# VIMS register map
Vendor: Texas Instruments
Peripheral module from a debugger description file (folder UCD3138R032RJA).
Registers are 32-bit, read-write, no defined reset value unless marked. A register's access mark holds for its fields unless they carry their own. Offsets are as the file gives them; lines under a group give offsets from that group; [hi:lo] are bit positions; {n}, {i} and the like mark numbered series; 'fields as' and 'values as' point back to an identical list; <NAME> marks a mode.

## VIMS — Versatile Instruction Memory System Controls memory access to the Flash and encapsulates the following instruction memories: - Boot ROM - Caches INTERNAL_NOTE: [Functional Spec](https://confluence.itg.ti.com/display/LPRF/Functional+Specification) [Simple Block Diagram](https://confluence.itg.ti.com/display/LPRF/Functional+Specification)
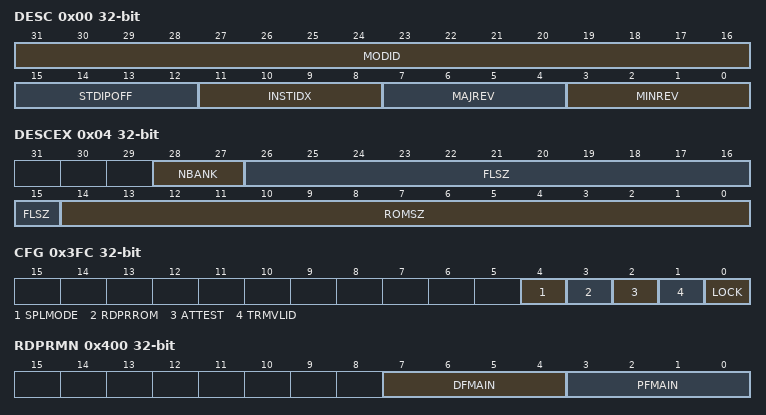
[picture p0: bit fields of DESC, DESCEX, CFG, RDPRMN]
0x00 DESC ro — Description Register. This register provides IP module ID, revision information, instance index and standard MMR registers offset.
  [31:16] MODID — Module identification contains a unique peripheral identification number.
  [15:12] STDIPOFF — Standard IP MMR block offset. Standard IP MMRs are the set of from aggregated IRQ registers till DTB. 0: Standard IP MMRs do not exist 0x1-0xF: Standard IP MMRs begin at offset of (64*[STDIPOFF] from the base IP address)
  [11:8] INSTIDX — IP Instance ID number. If multiple instances of IP exist in the device, this field can identify the instance number (0-15).
  [7:4] MAJREV — Major revision of IP
  [3:0] MINREV — Minor revision of IP
0x04 DESCEX ro — Extended Description Register.This register describes the configuration of VIMS.
  [28:27] NBANK — Number of Flash banks
  [26:15] FLSZ — FLASH size in Kilo Bytes. The total FLASH size is (FLSZ + 1) KB
  [14:0] ROMSZ — ROM size in Kilo Bytes. The total ROM size is (ROMSZ + 1) KB
0x08 FLWS1T — Flash Wait State 1T. This register is used to specify the number of waitstates necessary for accessing the flash in 1T mode.
  [3:0] VAL — Flash read wait states for 1T accesses
    {v}=WS{v} (Wait state value {v}) (v=0..15)
0x0C FLWS2T — Flash Wait State 1T. This register is used to specify the number of waitstates necessary for accessing the flash in 2T mode. This register is writable only when [CFG.LOCK] is 1
  [3:0] VAL — Flash read wait states for 2T accesses
    {v}=WS{v} (Wait state value {v}) (v=0..15)
0x18 PTRMC0 — FLASH Pump trim Bank 0. This register stores different PUMP trims. This register is writable only when [CFG.LOCK] is 1
  [31:0] VALUE — Flash charge pump trim value.
{0x20+8i} B{i}TRMC0 (i=0..2) — FLASH Bank {i} Trim [31:0]. This register stores different bank trims. This register is writable only when [CFG.LOCK] is 1
  [31:0] VALUE — Flash bank trim value.
0x100 FLBLCK — Flash Block. This register is used to block user read, write and erase operation to flash. This register is sticky 1 and writable only when [CFG.LOCK] is 1
  [0] ACCESS — Flash Access
    0=ALLOW; 1=BLOCK
0x3FC CFG — Configuration Register. This register is used for VIMS configuration. This register is writable only when [CFG.LOCK] is 1
  [4] SPLMODE — Split Mode. The logical address space is split into two equal regions
    0=DIS (Disable); 1=EN (Enable)
  [3] RDPRROM — ROM Read Protection Disable
    0=EN (Enable); 1=DIS (Disable)
  [2] ATTEST — This bit is used to enable flash test mode.
    0=DIS (Disable); 1=EN (Enable)
  [1] TRMVLID — TRIM Valid. This bit indicates if flash charge pump and bank trim values are as applicable.
    0=INVLID (Invalid); 1=VLID (Valid)
  [0] LOCK — Lock. Lock VIMS configuration. This bit is sticky '0' and when 0 write protects following registers FLWS1T FLWS2T PTRMC0 B0TRMC0 B1TRMC0 B2TRMC0 FLBLCK CFG
    0=EN (Configuration registers are locked for writing); 1=DIS (Configuration registers are open for writing)
0x400 RDPRMN — Read Protect Main. First 8KB of flash main region can be protected with granularity of 1KB. This register is sticky 0
  [7:4] DFMAIN — Data Flash Main protection configuration value. Undefined values will read protect whole protectable region or whole data flash; For 4KB paperspin option, values from 12(0xB) to 0(0x0) will protect whole 4KB data flash
    7=PROT_8KB (Protect whole DF 8KB); 8=PROT_7KB (Protect First 7KB); 9=PROT_6KB (Protect First 6KB); 10=PROT_5KB (Protect First 5KB); 11=PROT_4KB (Protect First 4KB); 12=PROT_3KB (Protect First 3KB); 13=PROT_2KB (Protect First 2KB); 14=PROT_1KB (Protect First 1KB); 15=PROT_0KB (Protection is Disabled)
  [3:0] PFMAIN — Program Flash Main protection configuration value. Undefined values will read protect whole protectable region
    7=PROT_8KB (Protect First 8KB); 8=PROT_7KB (Protect First 7KB); 9=PROT_6KB (Protect First 6KB); 10=PROT_5KB (Protect First 5KB); 11=PROT_4KB (Protect First 4KB); 12=PROT_3KB (Protect First 3KB); 13=PROT_2KB (Protect First 2KB); 14=PROT_1KB (Protect First 1KB); 15=PROT_0KB (Protection is Disabled)
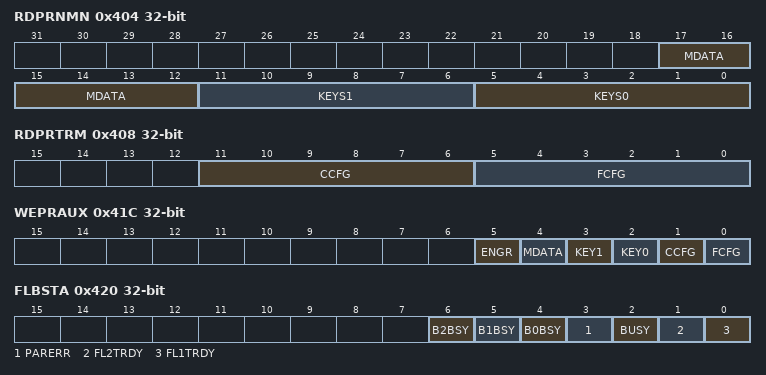
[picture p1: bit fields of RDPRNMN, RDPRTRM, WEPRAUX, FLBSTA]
0x404 RDPRNMN — Read Protect Non-Main regions.
  [all] fields
    31=PROT_1KB (Protect whole 1KB); 32=PROT_992B (Protect Last 992B); 33=PROT_960B (Protect Last 960B); 34=PROT_928B (Protect Last 928B); 60=PROT_96B (Protect Last 96B); 61=PROT_64B (Protect Last 64B); 62=PROT_32B (Protect Last 32B); 63=PROT_0B (Protection is Disabled)
  [17:12] MDATA — Metadata read protection configuration. 1024 bytes of Metadata can be protected with granularity of 32Bytes. Protection is disabled for 63(0x3F). The values ranging from 32(0x20) to 62(0x3E) will protect 32B spaces in the region. Values from 0(0x00) to 31(0x1F) will protect whole region. This field is sticky 0.
  [11:6] KEYS1 — KEY1 read protection configuration. 1024 bytes of KEY1 can be protected with granularity of 32Bytes. Protection is disabled for 63(0x3F). The values ranging from 32(0x20) to 62(0x3E) will protect 32B spaces in the region. Values from 0(0x00) to 31(0x1F) will protect whole region. This field is sticky 0.
  [5:0] KEYS0 — KEY0 read protection configuration. 1024 bytes of KEY0 can be protected with granularity of 32Bytes. Protection is disabled for 63(0x3F). The values ranging from 32(0x20) to 62(0x3E) will protect 32B spaces in the region. Values from 0(0x00) to 31(0x1F) will protect whole region. This field is sticky 0.
0x408 RDPRTRM — Read Protect Trim
  [11:6] CCFG — CCFG read protection configuration. 1024 bytes of CCFG can be protected with granularity of 16Bytes. Protection is disabled for 63(0x3F). The values ranging from 32(0x20) to 62(0x3E) will protect 16B spaces in the region. Values from 0(0x00) to 31(0x1F) will protect whole region. This field is sticky 0.
    31=PROT_512B (Protect whole 512B); 32=PROT_496B (Protect Last 496B); 33=PROT_480B (Protect Last 480B); 34=PROT_464B (Protect Last 464B); 60=PROT_48B (Protect Last 48B); 61=PROT_32B (Protect Last 32B); 62=PROT_16B (Protect Last 16B); 63=PROT_0B (Protection is Disabled)
  [5:0] FCFG — FCFG read protection configuration. 1024 bytes of FCFG can be protected with granularity of 16Bytes. Protection is disabled for 63(0x3F). The values ranging from 32(0x20) to 62(0x3E) will protect 16B spaces in the region. Values from 0(0x00) to 31(0x1F) will protect whole region. This field is sticky 0.
    values as CCFG
0x40C RDPREGR — Read Protect ENGR. This register is sticky 0
  [0] ENGR — ENGR read protection configuration.
0x410 WEPRA0 — Write Erase Protect Main for Bank-0 (Program Flash Bank-0). This register allows the first 32 sectors of the program flash bank 0 main region to be protected from program or erase, with 1 bit protecting each sector (sector 0 to sector 31). This register is sticky 0.
  [31:0] VAL — Flash write/erase protection configuration value.
0x414 WEPRA1 — Write Erase Protect Main Bank 1 (Program Flash Bank-1). This register allows the first 32 sectors of the program flash bank 1 main region to be protected from program or erase, with 1 bit protecting each sector (sector 0 to sector 31). This register is sticky 0.
  [31:0] VAL — Flash write/erase protection configuration value.
0x418 WEPRA2 — Write Erase Protect Main Bank 2 (Data Flash Bank). This register allows the first 8 sectors of the data flash bank main region to be protected from program or erase, with 1 bit protecting each sector (sector 0 to sector 7). This register is sticky 0.
  [7:0] VAL — Flash write/erase protection configuration value.
0x41C WEPRAUX — Write Erase Protect Auxillary. Flash Write/Erase protection for Non-Main, TRIM and ENGR Regions. This register is sticky 0
  [5] ENGR — Write/Erase Protection for ENGR
  [4] MDATA — Write/Erase Protection for MDATA
  [3] KEY1 — Write/Erase Protection for KEY1
  [2] KEY0 — Write/Erase Protection for KEY0
  [1] CCFG — Write/Erase Protection for CCFG
  [0] FCFG — Write/Erase Protection for FCFG
0x420 FLBSTA ro — Flash Status. This register is used to indicate status of flash.
  [6] B2BSY — Bank 2 Busy. This bit indicates if flash Bank 2 is busy.
    0=IDLE; 1=BUSY
  [5] B1BSY — Bank 1 Busy. This bit indicates if flash Bank 1 is busy.
    0=IDLE; 1=BUSY
  [4] B0BSY — Bank 0 Busy. This bit indicates if flash Bank 0 is busy.
    0=IDLE; 1=BUSY
  [3] PARERR — Parity Error. This bit indicates parity error on write/erase & read protection MMRs. This bit is sticky when set to 1 by hardware.
    0=NOERR (No Error); 1=ERR (Error)
  [2] BUSY — This bit indicates if flash is busy.
    0=IDLE; 1=BUSY
  [1] FL2TRDY — Flash 2T Ready. This bit indicates if flash is ready in 2T mode.
    0=NOTRDY (Not Ready); 1=RDY (Ready)
  [0] FL1TRDY — Flash 1T Ready. This bit indicates if flash is ready in 1T mode.
    0=NOTRDY (Not Ready); 1=RDY (Ready)
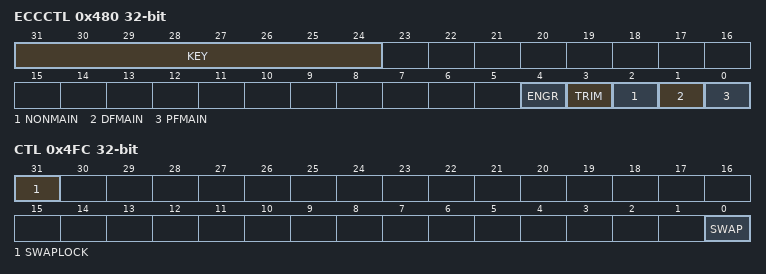
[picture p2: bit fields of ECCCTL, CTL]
0x480 ECCCTL access per field — ECC Configuration Control Register.
  [31:24] KEY wo — ECCCTL Key
    44=VALID_KEY (Valid Key to update ECC configuration)
  [4] ENGR rw — Configure ECC check for Engr region read.
    0=DISABLE (ECC is disabled); 1=ENABLE (ECC is enabled)
  [3] TRIM rw — Configure ECC check for Trim region read.
    0=DISABLE (ECC is disabled); 1=ENABLE (ECC is enabled)
  [2] NONMAIN rw — Configure ECC check for Non Main region read.
    0=DISABLE (ECC is disabled); 1=ENABLE (ECC is enabled)
  [1] DFMAIN rw — Configure ECC check for Data Flash Main region read.
    0=DISABLE (ECC is disabled); 1=ENABLE (ECC is enabled)
  [0] PFMAIN rw — Configure ECC check for Program Flash Main region reads.
    0=DISABLE (ECC is disabled); 1=ENABLE (ECC is enabled)
0x4FC CTL — Control Register.
  [31] SWAPLOCK — Swap Lock. If set, [CTL.SWAP] bit is blocked for writing. This bit is sticky 1
    0=UNLOCK (Unlocked); 1=LOCK (Locked)
  [0] SWAP — Swaps the logical to physical bank mapping. This bit has no effect if [CTL.SPLMODE] is 0 and is writable ony when [CTL.SWAPLOCK] is 0
    0=NOSWAP (Bank is not swapped); 1=SWAPED (Bank is swapped)
0x800 DTB — Digital test bus control register. This register can be used to bring out IP internal signals to the pads for observation. 8 signals can be observed per select value.
  [3:0] SEL — Digital test bus selection mux control. Non-zero select values output a 8 bit selected group of signals per value.
    0=DTB Signal Set-0 (Parity and Boot done Signals); 1=DTB Signal Set-1 (CAHB Decoder and Firewall signals); 2=DTB Signal Set-2 (SAHB Decoder and Firewall signals); 3=DTB Signal Set-3 (ECC Fault and ROM signals); 4=DTB Signal Set-4 (Flash Disconnect-handshaking signals); 5=DTB Signal Set-5 (Flash Ready and Swap signals); 6=DTB Signal Set-6 (Fxbar Signals); 7=DTB Signal Set-7 (Address Translation Signals)
